# ESP32S31_RADIO register map
Vendor: Espressif; Series: ESP32-S31; File version: 3.52
Registers are 32-bit, read-write, no defined reset value unless marked. A register's access mark holds for its fields unless they carry their own. Offsets are from the block's base; [hi:lo] are bit positions; {n}, {i} and the like mark numbered series; 'fields as' and 'values as' point back to an identical list.

## WIFI_MAC_AUX_TSF_CONTROL — SoftAP, NAN and broadcast-TWT TSF control words. Complete public leaves prove their addresses and exact enable/mode masks; unrelated bits and hardware transition rules remain unnamed.
Base 0x2010D860
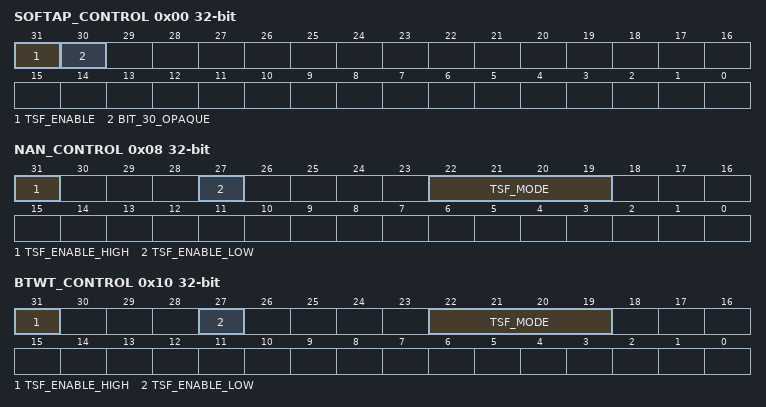
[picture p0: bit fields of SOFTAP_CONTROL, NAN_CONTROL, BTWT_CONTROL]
0x00 SOFTAP_CONTROL — Project-assigned name. Complete hal_disable_softap_tsf clears bits 31:30. Generic TSF enable/disable leaves independently identify bit 31 as the domain enable; bit 30 remains unknown.
  [31] TSF_ENABLE — Project-assigned name.
  [30] BIT_30_OPAQUE — Opaque: meaning not established.
0x08 NAN_CONTROL — Project-assigned name. Complete NAN enable/disable leaves use the same two-stage gate and mode transaction as station TSF at this distinct word.
  [31] TSF_ENABLE_HIGH — Project-assigned name.
  [27] TSF_ENABLE_LOW — Project-assigned name.
  [22:19] TSF_MODE — Project-assigned name.
0x10 BTWT_CONTROL — Project-assigned name. Complete hal_enable_sta_btwt_tsf enables or disables the broadcast-TWT TSF domain using the same gate and mode masks as station TSF.
  fields as NAN_CONTROL

## WIFI_MAC_TXRX_PREFIX — Eighteen direct fresh-read RMW edges before the first external HE callback in complete mac_txrx_init; complete hal_init later repeats the bit-28 set edge.
Base 0x201040FC
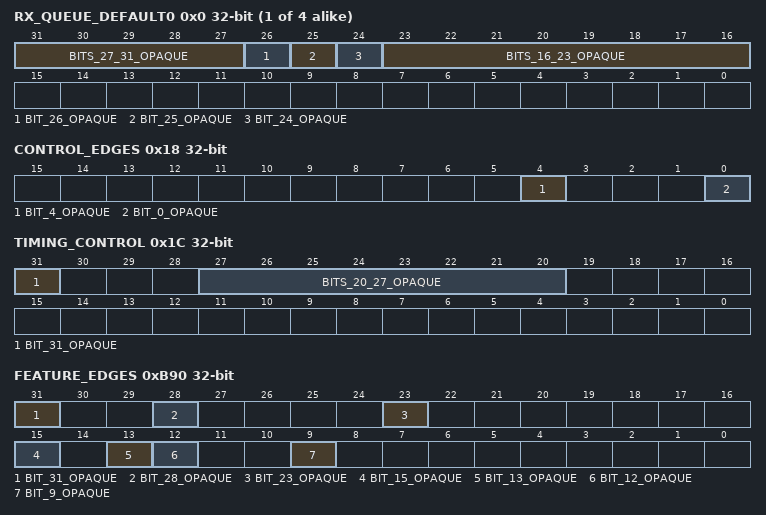
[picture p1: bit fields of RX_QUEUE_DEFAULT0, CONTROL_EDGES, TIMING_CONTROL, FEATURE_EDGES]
{0x0+4i} RX_QUEUE_DEFAULT{i} (i=0..3) — Project-assigned name. Four queue words have their high half cleared independently; queue zero and one then receive separate bit-24 and bit-26 set edges.
  [31:27] BITS_27_31_OPAQUE — Opaque: meaning not established.
  [26] BIT_26_OPAQUE — Opaque: meaning not established.
  [25] BIT_25_OPAQUE — Opaque: meaning not established.
  [24] BIT_24_OPAQUE — Opaque: meaning not established.
  [23:16] BITS_16_23_OPAQUE — Opaque: meaning not established.
0x18 CONTROL_EDGES — Project-assigned name. Complete prefix sets bit 0, then bit 4 through a second fresh-read RMW.
  [4] BIT_4_OPAQUE — Opaque: meaning not established.
  [0] BIT_0_OPAQUE — Opaque: meaning not established.
0x1C TIMING_CONTROL — Project-assigned name. Complete prefix sets bit 31, then replaces bits 27:20 with 0x1b in a separate RMW.
  [31] BIT_31_OPAQUE — Opaque: meaning not established.
  [27:20] BITS_20_27_OPAQUE — Opaque: meaning not established.
0xB90 FEATURE_EDGES — Project-assigned name. Four separately ordered prefix updates: first set bits 31,23,15,13 together; set bit 12; set bit 28; later set bit 9 after queue defaults. Complete hal_init repeats the bit-28 set after antenna initialization.
  [31] BIT_31_OPAQUE — Opaque: meaning not established.
  [28] BIT_28_OPAQUE — Opaque: meaning not established. Set once in mac_txrx_init and again at hal_init offset 0xe2 after the interrupt-mask store.
  [23] BIT_23_OPAQUE — Opaque: meaning not established.
  [15] BIT_15_OPAQUE — Opaque: meaning not established.
  [13] BIT_13_OPAQUE — Opaque: meaning not established.
  [12] BIT_12_OPAQUE — Opaque: meaning not established.
  [9] BIT_9_OPAQUE — Opaque: meaning not established.
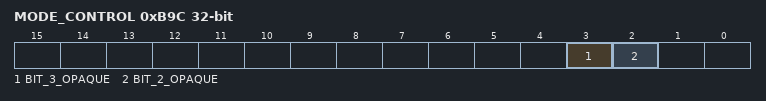
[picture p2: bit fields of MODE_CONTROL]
0xB9C MODE_CONTROL — Project-assigned name. Canonical multifunction word. Complete mac_txrx prefix clears bit 3; the HE init suffix independently sets bit 2.
  [3] BIT_3_OPAQUE — Opaque: meaning not established.
  [2] BIT_2_OPAQUE — Opaque: meaning not established. Complete HE init suffix sets bit 2.
0xBA4 SHARED_ENABLE_CONTROL — Project-assigned name. Final prefix RMW sets bits 1:0 together immediately before the first HE callback.
  [1:0] BITS_0_1_OPAQUE — Opaque: meaning not established.

## WIFI_MAC_TXRX_CALLBACKS — Hardware effects of the three HE callbacks between the direct mac_txrx_init prefix and suffix. Diagnostic logging calls are intentionally omitted.
Base 0x2010444C
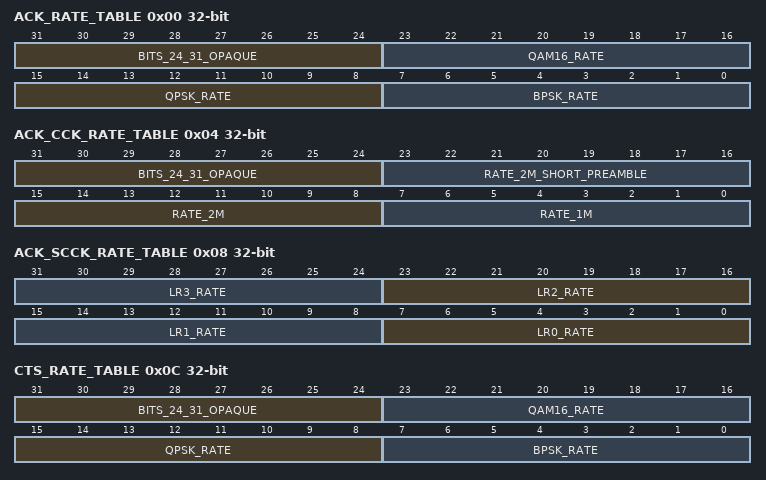
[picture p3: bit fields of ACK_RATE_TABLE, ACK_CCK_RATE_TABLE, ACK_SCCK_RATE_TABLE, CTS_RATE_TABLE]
0x00 ACK_RATE_TABLE — Project-assigned name. ACK_TAB0. hal_he_set_ack_rate(0) publishes 0x00090a0b; complete dbg_read_ack_rate names its three byte lanes.
  [31:24] BITS_24_31_OPAQUE — Opaque: meaning not established.
  [23:16] QAM16_RATE — Project-assigned name.
  [15:8] QPSK_RATE — Project-assigned name.
  [7:0] BPSK_RATE — Project-assigned name.
0x04 ACK_CCK_RATE_TABLE — Project-assigned name. ACK_TAB1. hal_he_set_ack_rate(0) publishes 0x00050100; complete dbg_read_ack_rate names the 1M, 2M and short-preamble 2M lanes.
  [31:24] BITS_24_31_OPAQUE — Opaque: meaning not established.
  [23:16] RATE_2M_SHORT_PREAMBLE — Project-assigned name.
  [15:8] RATE_2M — Project-assigned name.
  [7:0] RATE_1M — Project-assigned name.
0x08 ACK_SCCK_RATE_TABLE — Project-assigned name. ACK_SCCKTAB, decoded by complete dbg_read_ack_rate. The cold setter does not alter this word.
  [8n+7:8n] LR{n}_RATE (n=0..3) — Project-assigned name.
0x0C CTS_RATE_TABLE — Project-assigned name. CTS_TAB0. hal_he_set_ack_rate(0) publishes 0x00090a0b; complete dbg_read_cts_rate names its three byte lanes.
  fields as ACK_RATE_TABLE
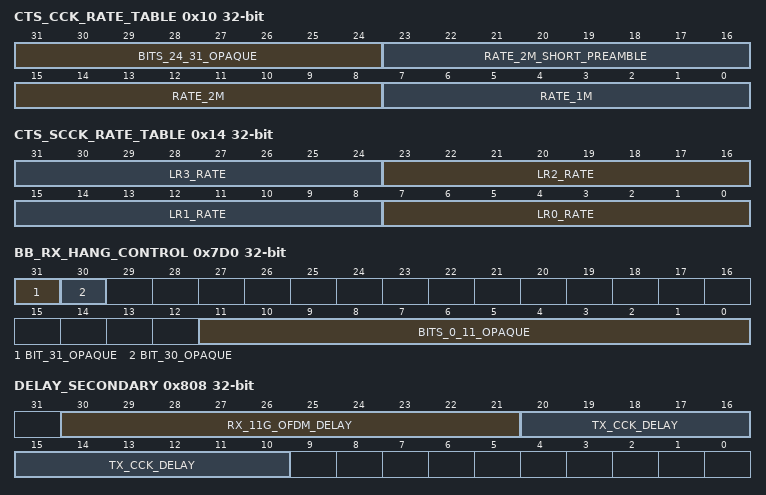
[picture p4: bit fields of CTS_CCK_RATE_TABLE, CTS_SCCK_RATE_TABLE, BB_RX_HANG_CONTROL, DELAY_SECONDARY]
0x10 CTS_CCK_RATE_TABLE — Project-assigned name. CTS_TAB1. hal_he_set_ack_rate(0) publishes 0x00050100; complete dbg_read_cts_rate names the 1M, 2M and short-preamble 2M lanes.
  fields as ACK_CCK_RATE_TABLE
0x14 CTS_SCCK_RATE_TABLE — Project-assigned name. CTS_SCCKTAB, decoded by complete dbg_read_cts_rate. The cold setter does not alter this word.
  [8n+7:8n] LR{n}_RATE (n=0..3) — Project-assigned name.
0x7D0 BB_RX_HANG_CONTROL — Project-assigned name. Canonical multifunction word. hal_he_set_bbrxhung_time(0) replaces the low twelve bits with 0x00f; the direct mac_txrx_init suffix later sets bits 31 and 30 through two fresh-read RMWs.
  [31] BIT_31_OPAQUE — Opaque: meaning not established.
  [30] BIT_30_OPAQUE — Opaque: meaning not established.
  [11:0] BITS_0_11_OPAQUE — Opaque: meaning not established.
0x808 DELAY_SECONDARY — Project-assigned name. WDEVDELAY1. On-chip hal_he_set_mac_delay uses random slot 0..10 for WDEV_RX_11G_OFDM_DELAY, while complete phy_sifs_reg_init writes 0xea to that field.
  [30:21] RX_11G_OFDM_DELAY — Project-assigned name.
  [20:10] TX_CCK_DELAY — Project-assigned name.
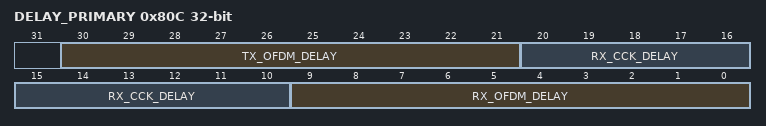
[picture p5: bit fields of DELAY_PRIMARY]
0x80C DELAY_PRIMARY — Project-assigned name. WDEVDELAY. On-chip hal_he_set_mac_delay performs separate RMWs for WDEV_RXCCK_DELAY, WDEV_RXOFDM_DELAY and WDEV_TXOFDM_DELAY; complete phy_sifs_reg_init writes 0x3b8 and 0xf0 to the first two fields.
  [30:21] TX_OFDM_DELAY — Project-assigned name.
  [20:10] RX_CCK_DELAY — Project-assigned name.
  [9:0] RX_OFDM_DELAY — Project-assigned name.
